# AT32UC3C0512C device description
Architecture: AVR32_UC3; Family: AVR UC3
Registers are 32-bit, read-write, reset 0x0 unless marked. A register's access mark holds for its fields unless they carry their own. Offsets are from the block's base; [hi:lo] are bit positions; 'fields as' and 'values as' point back to an identical list.

## QDEC — Quadrature Decoder
Instances: QDEC0 0xffff5000, QDEC1 0xffff5400
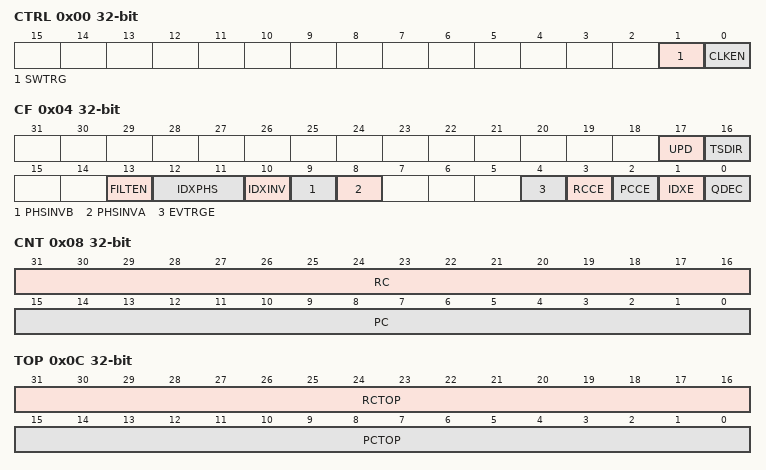
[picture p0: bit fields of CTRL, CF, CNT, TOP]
0x00 CTRL
  [1] SWTRG — Software trigger
  [0] CLKEN — QDEC clock enable
0x04 CF
  [17] UPD — Up/Down timer mode
  [16] TSDIR — Timer set direction
  [13] FILTEN — Input digital filter enable
  [12:11] IDXPHS — QEPI detection phase
  [10] IDXINV — QEPI phase
  [9] PHSINVB — QEPB phase
  [8] PHSINVA — QEPA phase
  [4] EVTRGE — Event trigger enable
  [3] RCCE — Revolution counter compare enable
  [2] PCCE — Position counter compare enable
  [1] IDXE — Index Enable
  [0] QDEC — QDEC Mode.
0x08 CNT
  [31:16] RC — Revolution Counter
  [15:0] PC — Position Counter
0x0C TOP
  [31:16] RCTOP — Revolution Counter top value
  [15:0] PCTOP — Position Counter top value
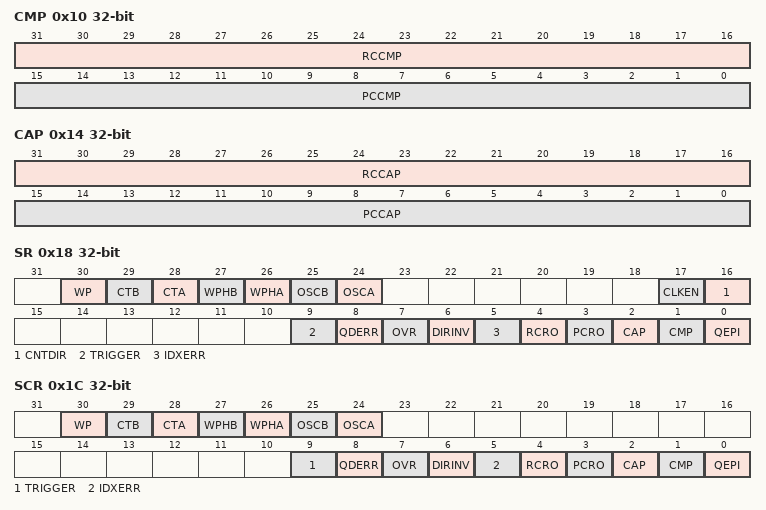
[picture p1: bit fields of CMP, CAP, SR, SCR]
0x10 CMP
  [31:16] RCCMP — Revolution Counter Compare Value
  [15:0] PCCMP — Position Counter Compare Value
0x14 CAP ro
  [31:16] RCCAP — Revolution Capture
  [15:0] PCCAP — Position Capture
0x18 SR ro
  [30] WP — Wrong position
  [29] CTB — QEPB Cross Talk
  [28] CTA — QEPA Cross Talk
  [27] WPHB — QEPB Wrong phase
  [26] WPHA — QEPA Wrong phase
  [25] OSCB — QEPB Oscillation
  [24] OSCA — QEPA Oscillation
  [17] CLKEN — QDEC counter clock status
  [16] CNTDIR — Counter Direction.
  [9] TRIGGER — Trigger event occurence.
  [8] QDERR — Illegal quadrature signals transition.
  [7] OVR — Overrun capture.
  [6] DIRINV — Count Direction Inversion
  [5] IDXERR — Index Error
  [4] RCRO — Revolution Counter Roll Over
  [3] PCRO — Position Counter Roll Over
  [2] CAP — Counter Capture
  [1] CMP — Counter Compare
  [0] QEPI — Index Signal Detection
0x1C SCR wo
  [30] WP — Wrong position
  [29] CTB — QEPB Cross Talk
  [28] CTA — QEPA Cross Talk
  [27] WPHB — QEPB Wrong phase
  [26] WPHA — QEPA Wrong phase
  [25] OSCB — QEPB Oscillation
  [24] OSCA — QEPA Oscillation
  [9] TRIGGER — Trigger event occurence.
  [8] QDERR — Illegal quadrature signals transition.
  [7] OVR — Overrun capture.
  [6] DIRINV — Count Direction Inversion
  [5] IDXERR — Index Error
  [4] RCRO — Revolution Counter Roll Over
  [3] PCRO — Position Counter Roll Over
  [2] CAP — Counter Capture
  [1] CMP — Counter Compare
  [0] QEPI — Index Signal Detection
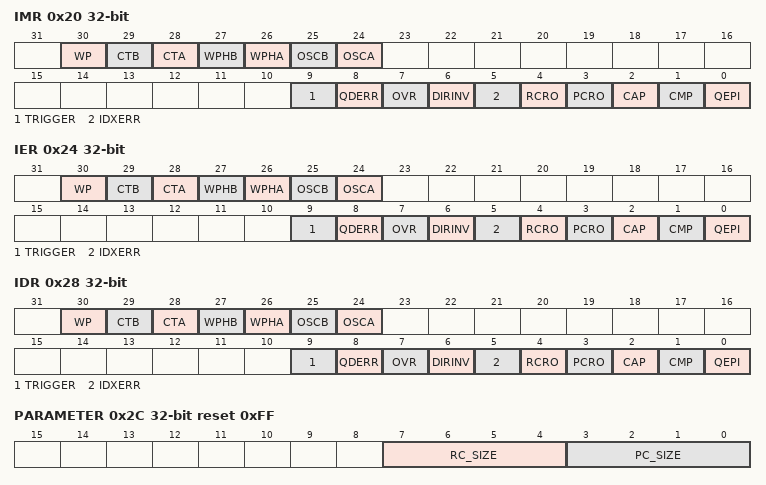
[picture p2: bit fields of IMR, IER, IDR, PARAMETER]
0x20 IMR ro
  [30] WP — Wrong position occurs.
  [29] CTB — Cross Talk occurs on line QEPB.
  [28] CTA — Cross Talk occurs on line QEPA.
  [27] WPHB — Wrong phase occurs on line QEPB.
  [26] WPHA — Wrong phase occurs on line QEPA.
  [25] OSCB — Oscillation occurs on line QEPB.
  [24] OSCA — Oscillation occurs on line QEPA.
  [9] TRIGGER — Trigger occurence.
  [8] QDERR — Illegal quadrature signals transition.
  [7] OVR — Overrun capture.
  [6] DIRINV — Count Direction Inversion Mask Bit.
  [5] IDXERR — Index Error Detection Mask Bit.
  [4] RCRO — Revolution Counter Roll Over Detection Mask Bit.
  [3] PCRO — Position Counter Roll Over Detection Mask Bit.
  [2] CAP — Counter Capture Event Detection Mask Bit.
  [1] CMP — Counter Compare Event Detection Mask Bit.
  [0] QEPI — Index Signal Detection Mask Bit.
0x24 IER wo
  [30] WP — Wrong position occurs.
  [29] CTB — Cross Talk occurs on line QEPB.
  [28] CTA — Cross Talk occurs on line QEPA.
  [27] WPHB — Wrong phase occurs on line QEPB.
  [26] WPHA — Wrong phase occurs on line QEPA.
  [25] OSCB — Oscillation occurs on line QEPB.
  [24] OSCA — Oscillation occurs on line QEPA.
  [9] TRIGGER — Trigger occurence.
  [8] QDERR — Illegal quadrature signals transition.
  [7] OVR — Overrun capture
  [6] DIRINV — Count Direction Inversion Mask Bit.
  [5] IDXERR — Index Error Detection Mask Bit.
  [4] RCRO — Revolution Counter Roll Over Detection Mask Bit.
  [3] PCRO — Position Counter Roll Over Detection Mask Bit.
  [2] CAP — Counter Capture Event Detection Mask Bit.
  [1] CMP — Counter Compare Event Detection Mask Bit.
  [0] QEPI — Index Signal Detection Mask Bit.
0x28 IDR wo
  fields as IER
0x2C PARAMETER ro reset 0xFF — PAR register
  [7:4] RC_SIZE — Size-1 of RC registers
  [3:0] PC_SIZE — Size-1 of PC registers
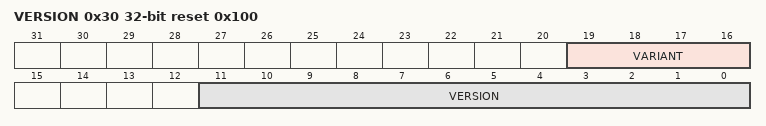
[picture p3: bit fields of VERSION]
0x30 VERSION ro reset 0x100
  [19:16] VARIANT — Reserved. Value subject to change. No functionality associated.
  [11:0] VERSION — Version of the module
